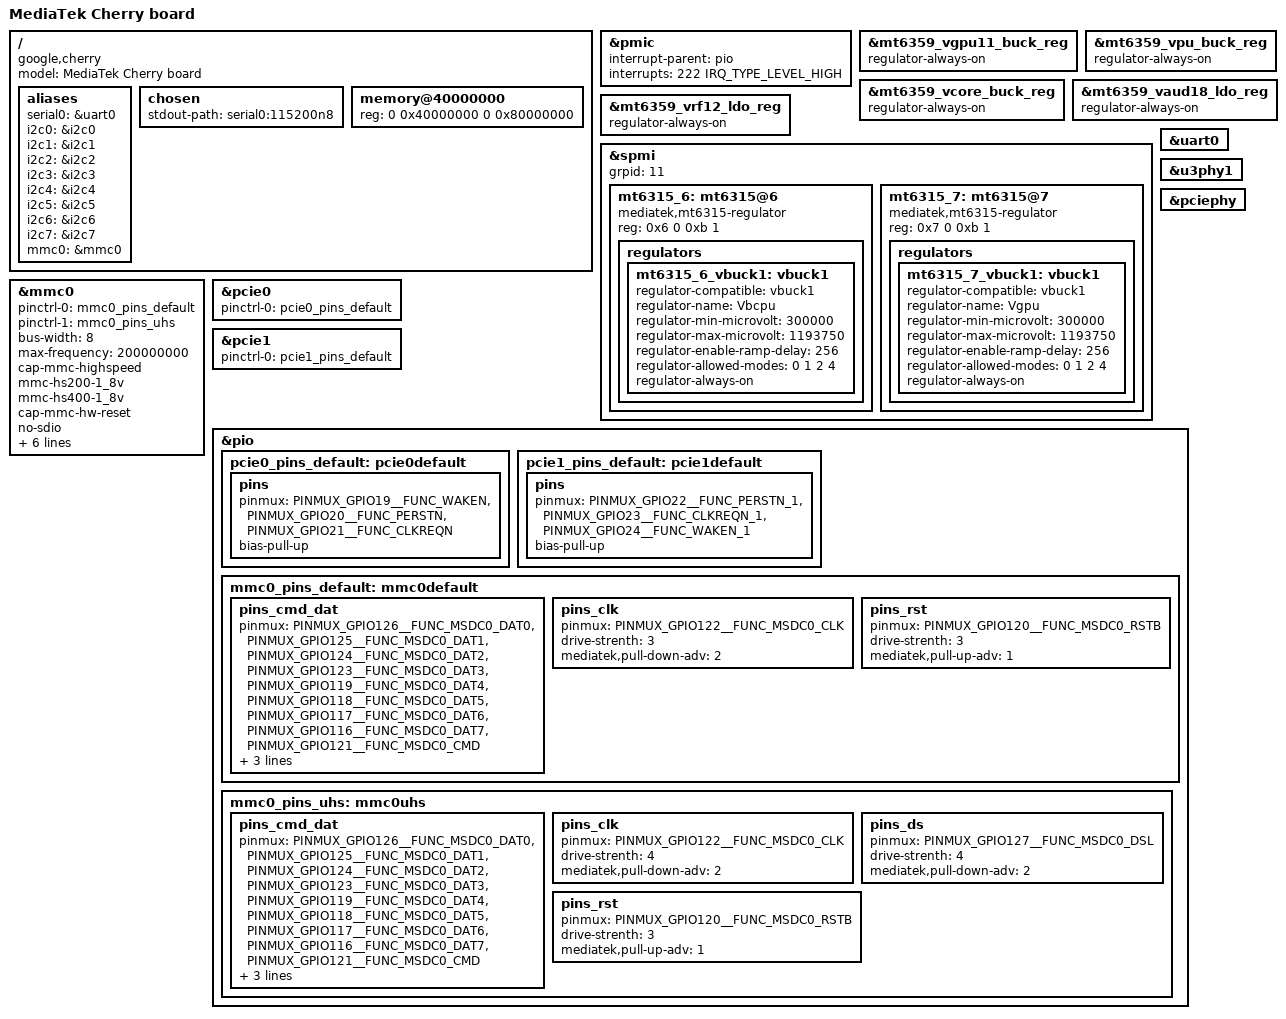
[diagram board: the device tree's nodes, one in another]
// SPDX-License-Identifier: (GPL-2.0 OR MIT)
/*
 * Copyright (C) 2021 MediaTek Inc.
 */
/dts-v1/;
#include <dt-bindings/gpio/gpio.h>
#include "mt8195.dtsi"
#include "mt6359.dtsi"

/ {
	model = "MediaTek Cherry board";
	compatible = "google,cherry", "mediatek,mt8195";

	aliases {
		serial0 = &uart0;
		i2c0 = &i2c0;
		i2c1 = &i2c1;
		i2c2 = &i2c2;
		i2c3 = &i2c3;
		i2c4 = &i2c4;
		i2c5 = &i2c5;
		i2c6 = &i2c6;
		i2c7 = &i2c7;
		mmc0 = &mmc0;
	};

	chosen {
		stdout-path = "serial0:115200n8";
	};

	memory@40000000 {
		device_type = "memory";
		reg = <0 0x40000000 0 0x80000000>;
	};
};

&pmic {
	interrupt-parent = <&pio>;
	interrupts = <222 IRQ_TYPE_LEVEL_HIGH>;
};

/* for CORE */
&mt6359_vgpu11_buck_reg {
	regulator-always-on;
};

/* for CORE SRAM */
&mt6359_vpu_buck_reg {
	regulator-always-on;
};

/* for CPU-L */
&mt6359_vcore_buck_reg {
	regulator-always-on;
};

&mt6359_vaud18_ldo_reg {
	regulator-always-on;
};

&mt6359_vrf12_ldo_reg {
	regulator-always-on;
};

&spmi {
	grpid = <11>;
	mt6315_6: mt6315@6 {
		compatible = "mediatek,mt6315-regulator";
		reg = <0x6 0 0xb 1>;

		regulators {
			mt6315_6_vbuck1: vbuck1 {
				regulator-compatible = "vbuck1";
				regulator-name = "Vbcpu";
				regulator-min-microvolt = <300000>;
				regulator-max-microvolt = <1193750>;
				regulator-enable-ramp-delay = <256>;
				regulator-allowed-modes = <0 1 2 4>;
				regulator-always-on;
			};
		};
	};

	mt6315_7: mt6315@7 {
		compatible = "mediatek,mt6315-regulator";
		reg = <0x7 0 0xb 1>;

		regulators {
			mt6315_7_vbuck1: vbuck1 {
				regulator-compatible = "vbuck1";
				regulator-name = "Vgpu";
				regulator-min-microvolt = <300000>;
				regulator-max-microvolt = <1193750>;
				regulator-enable-ramp-delay = <256>;
				regulator-allowed-modes = <0 1 2 4>;
				regulator-always-on;
			};
		};
	};
};

&uart0 {
	status = "okay";
};

&u3phy1 {
	status = "okay";
};

&mmc0 {
	status = "okay";
	pinctrl-names = "default", "state_uhs";
	pinctrl-0 = <&mmc0_pins_default>;
	pinctrl-1 = <&mmc0_pins_uhs>;
	bus-width = <8>;
	max-frequency = <200000000>;
	cap-mmc-highspeed;
	mmc-hs200-1_8v;
	mmc-hs400-1_8v;
	cap-mmc-hw-reset;
	no-sdio;
	no-sd;
	hs400-ds-delay = <0x14c11>;
	host_id = <0>;
	vmmc-supply = <&mt6359_vemc_1_ldo_reg>;
	vqmmc-supply = <&mt6359_vufs_ldo_reg>;
	non-removable;
};

&pcie0 {
	pinctrl-names = "default";
	pinctrl-0 = <&pcie0_pins_default>;
	status = "okay";
};

&pcie1 {
	pinctrl-names = "default";
	pinctrl-0 = <&pcie1_pins_default>;
	status = "okay";
};

&pciephy {
	status = "okay";
};

&pio {
	pcie0_pins_default: pcie0default {
		pins {
			pinmux = <PINMUX_GPIO19__FUNC_WAKEN>,
				 <PINMUX_GPIO20__FUNC_PERSTN>,
				 <PINMUX_GPIO21__FUNC_CLKREQN>;
				 bias-pull-up;
		};
	};

	pcie1_pins_default: pcie1default {
		pins {
			pinmux = <PINMUX_GPIO22__FUNC_PERSTN_1>,
				 <PINMUX_GPIO23__FUNC_CLKREQN_1>,
				 <PINMUX_GPIO24__FUNC_WAKEN_1>;
				 bias-pull-up;
		};
	};

	mmc0_pins_default: mmc0default {
		pins_cmd_dat {
			pinmux = <PINMUX_GPIO126__FUNC_MSDC0_DAT0>,
				 <PINMUX_GPIO125__FUNC_MSDC0_DAT1>,
				 <PINMUX_GPIO124__FUNC_MSDC0_DAT2>,
				 <PINMUX_GPIO123__FUNC_MSDC0_DAT3>,
				 <PINMUX_GPIO119__FUNC_MSDC0_DAT4>,
				 <PINMUX_GPIO118__FUNC_MSDC0_DAT5>,
				 <PINMUX_GPIO117__FUNC_MSDC0_DAT6>,
				 <PINMUX_GPIO116__FUNC_MSDC0_DAT7>,
				 <PINMUX_GPIO121__FUNC_MSDC0_CMD>;
			input-enable;
			drive-strenth = <3>;
			mediatek,pull-up-adv = <1>;
		};

		pins_clk {
			pinmux = <PINMUX_GPIO122__FUNC_MSDC0_CLK>;
			drive-strenth = <3>;
			mediatek,pull-down-adv = <2>;
		};

		pins_rst {
			pinmux = <PINMUX_GPIO120__FUNC_MSDC0_RSTB>;
			drive-strenth = <3>;
			mediatek,pull-up-adv = <1>;
		};
	};

	mmc0_pins_uhs: mmc0uhs{
		pins_cmd_dat {
			pinmux = <PINMUX_GPIO126__FUNC_MSDC0_DAT0>,
				 <PINMUX_GPIO125__FUNC_MSDC0_DAT1>,
				 <PINMUX_GPIO124__FUNC_MSDC0_DAT2>,
				 <PINMUX_GPIO123__FUNC_MSDC0_DAT3>,
				 <PINMUX_GPIO119__FUNC_MSDC0_DAT4>,
				 <PINMUX_GPIO118__FUNC_MSDC0_DAT5>,
				 <PINMUX_GPIO117__FUNC_MSDC0_DAT6>,
				 <PINMUX_GPIO116__FUNC_MSDC0_DAT7>,
				 <PINMUX_GPIO121__FUNC_MSDC0_CMD>;
			input-enable;
			drive-strenth = <4>;
			mediatek,pull-up-adv = <1>;
		};

		pins_clk {
			pinmux = <PINMUX_GPIO122__FUNC_MSDC0_CLK>;
			drive-strenth = <4>;
			mediatek,pull-down-adv = <2>;
		};

		pins_ds {
			pinmux = <PINMUX_GPIO127__FUNC_MSDC0_DSL>;
			drive-strenth = <4>;
			mediatek,pull-down-adv = <2>;
		};

		pins_rst {
			pinmux = <PINMUX_GPIO120__FUNC_MSDC0_RSTB>;
			drive-strenth = <3>;
			mediatek,pull-up-adv = <1>;
		};
	};
};
